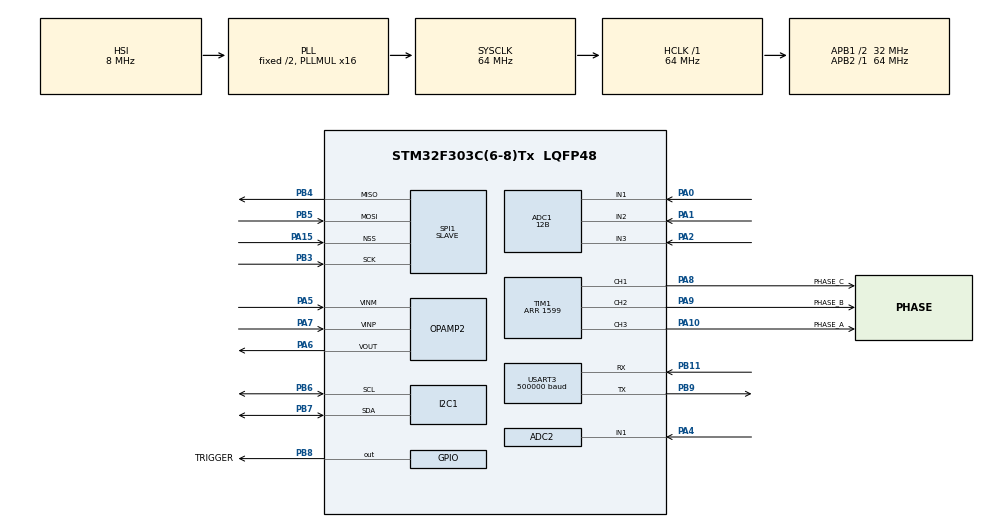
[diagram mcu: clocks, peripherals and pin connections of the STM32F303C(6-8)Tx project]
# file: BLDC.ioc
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ADC1.Channel-0\#ChannelRegularConversion=ADC_CHANNEL_1
ADC1.Channel-1\#ChannelRegularConversion=ADC_CHANNEL_2
ADC1.Channel-135\#ChannelRegularConversion=ADC_CHANNEL_1
ADC1.Channel-138\#ChannelRegularConversion=ADC_CHANNEL_2
ADC1.Channel-148\#ChannelRegularConversion=ADC_CHANNEL_3
ADC1.Channel-2\#ChannelRegularConversion=ADC_CHANNEL_3
ADC1.Channel-IN2=ADC_CHANNEL_2
ADC1.Channel-IN3=ADC_CHANNEL_3
ADC1.ClockPrescaler=ADC_CLOCK_ASYNC_DIV1
ADC1.ContinuousConvMode=DISABLE
ADC1.DMAContinuousRequests=ENABLE
ADC1.DataAlign=ADC_DATAALIGN_RIGHT
ADC1.DiscontinuousConvMode=DISABLE
ADC1.EOCSelection=ADC_EOC_SINGLE_CONV
ADC1.EnableAnalogWatchDog1=false
ADC1.EnableAnalogWatchDog2=false
ADC1.EnableAnalogWatchDog3=false
ADC1.EnableInjectedConversion=ENABLE
ADC1.EnableRegularConversion=ENABLE
ADC1.ExternalTrigConv=ADC_EXTERNALTRIGCONV_T1_TRGO2
ADC1.ExternalTrigConvEdge=ADC_EXTERNALTRIGCONVEDGE_RISING
ADC1.InjNumberOfConversion=0
ADC1.LowPowerAutoWait=DISABLE
ADC1.NbrOfConversion=3
ADC1.NbrOfConversionFlag=1
ADC1.Offset-0\#ChannelRegularConversion=0
ADC1.Offset-1\#ChannelRegularConversion=0
ADC1.Offset-135\#ChannelRegularConversion=0
ADC1.Offset-138\#ChannelRegularConversion=0
ADC1.Offset-148\#ChannelRegularConversion=0
ADC1.Offset-2\#ChannelRegularConversion=0
ADC1.OffsetNumber-0\#ChannelRegularConversion=ADC_OFFSET_NONE
ADC1.OffsetNumber-1\#ChannelRegularConversion=ADC_OFFSET_NONE
ADC1.OffsetNumber-135\#ChannelRegularConversion=ADC_OFFSET_NONE
ADC1.OffsetNumber-138\#ChannelRegularConversion=ADC_OFFSET_NONE
ADC1.OffsetNumber-148\#ChannelRegularConversion=ADC_OFFSET_NONE
ADC1.OffsetNumber-2\#ChannelRegularConversion=ADC_OFFSET_NONE
ADC1.Overrun=ADC_OVR_DATA_OVERWRITTEN
ADC1.Rank-0\#ChannelRegularConversion=1
ADC1.Rank-1\#ChannelRegularConversion=2
ADC1.Rank-135\#ChannelRegularConversion=1
ADC1.Rank-138\#ChannelRegularConversion=2
ADC1.Rank-148\#ChannelRegularConversion=3
ADC1.Rank-2\#ChannelRegularConversion=3
ADC1.Resolution=ADC_RESOLUTION_12B
ADC1.SamplingTime-0\#ChannelRegularConversion=ADC_SAMPLETIME_4CYCLES_5
ADC1.SamplingTime-1\#ChannelRegularConversion=ADC_SAMPLETIME_4CYCLES_5
ADC1.SamplingTime-135\#ChannelRegularConversion=ADC_SAMPLETIME_4CYCLES_5
ADC1.SamplingTime-138\#ChannelRegularConversion=ADC_SAMPLETIME_4CYCLES_5
ADC1.SamplingTime-148\#ChannelRegularConversion=ADC_SAMPLETIME_4CYCLES_5
ADC1.SamplingTime-2\#ChannelRegularConversion=ADC_SAMPLETIME_4CYCLES_5
ADC1.ScanConvMode=ADC_SCAN_ENABLE
ADC1.SubFamily=STM32F303x8
ADC1.master=1
ADC2.Channel-93\#ChannelRegularConversion=ADC_CHANNEL_3
ADC2.Channel-94\#ChannelRegularConversion=ADC_CHANNEL_1
ADC2.ClockPrescaler=ADC_CLOCK_ASYNC_DIV1
ADC2.ContinuousConvMode=DISABLE
ADC2.DMAContinuousRequests=ENABLE
ADC2.DataAlign=ADC_DATAALIGN_RIGHT
ADC2.DiscontinuousConvMode=DISABLE
ADC2.EOCSelection=ADC_EOC_SINGLE_CONV
ADC2.EnableAnalogWatchDog1=false
ADC2.EnableAnalogWatchDog2=false
ADC2.EnableAnalogWatchDog3=false
ADC2.EnableInjectedConversion=ENABLE
ADC2.EnableRegularConversion=ENABLE
ADC2.ExternalTrigConv=ADC_EXTERNALTRIGCONV_T15_TRGO
ADC2.ExternalTrigConvEdge=ADC_EXTERNALTRIGCONVEDGE_RISING
ADC2.InjNumberOfConversion=0
ADC2.LowPowerAutoWait=DISABLE
ADC2.NbrOfConversion=2
ADC2.NbrOfConversionFlag=1
ADC2.Offset-93\#ChannelRegularConversion=0
ADC2.Offset-94\#ChannelRegularConversion=0
ADC2.OffsetNumber-93\#ChannelRegularConversion=ADC_OFFSET_NONE
ADC2.OffsetNumber-94\#ChannelRegularConversion=ADC_OFFSET_NONE
ADC2.Overrun=ADC_OVR_DATA_OVERWRITTEN
ADC2.Rank-93\#ChannelRegularConversion=1
ADC2.Rank-94\#ChannelRegularConversion=2
ADC2.Resolution=ADC_RESOLUTION_12B
ADC2.SamplingTime-93\#ChannelRegularConversion=ADC_SAMPLETIME_7CYCLES_5
ADC2.SamplingTime-94\#ChannelRegularConversion=ADC_SAMPLETIME_7CYCLES_5
ADC2.ScanConvMode=ADC_SCAN_ENABLE
ADC2.SubFamily=STM32F303x8
Dma.ADC1.0.Direction=DMA_PERIPH_TO_MEMORY
Dma.ADC1.0.Instance=DMA1_Channel1
Dma.ADC1.0.MemDataAlignment=DMA_MDATAALIGN_HALFWORD
Dma.ADC1.0.MemInc=DMA_MINC_ENABLE
Dma.ADC1.0.Mode=DMA_CIRCULAR
Dma.ADC1.0.PeriphDataAlignment=DMA_PDATAALIGN_HALFWORD
Dma.ADC1.0.PeriphInc=DMA_PINC_DISABLE
Dma.ADC1.0.Priority=DMA_PRIORITY_LOW
Dma.ADC2.1.Direction=DMA_PERIPH_TO_MEMORY
Dma.ADC2.1.Instance=DMA1_Channel4
Dma.ADC2.1.MemDataAlignment=DMA_MDATAALIGN_HALFWORD
Dma.ADC2.1.MemInc=DMA_MINC_ENABLE
Dma.ADC2.1.Mode=DMA_CIRCULAR
Dma.ADC2.1.PeriphDataAlignment=DMA_PDATAALIGN_HALFWORD
Dma.ADC2.1.PeriphInc=DMA_PINC_DISABLE
Dma.ADC2.1.Priority=DMA_PRIORITY_LOW
Dma.Request0=ADC1
Dma.Request1=ADC2
Dma.Request2=SPI1_RX
Dma.Request3=SPI1_TX
Dma.Request4=USART3_TX
Dma.SPI1_RX.2.Direction=DMA_PERIPH_TO_MEMORY
Dma.SPI1_RX.2.Instance=DMA1_Channel6
Dma.SPI1_RX.2.MemDataAlignment=DMA_MDATAALIGN_BYTE
Dma.SPI1_RX.2.MemInc=DMA_MINC_ENABLE
Dma.SPI1_RX.2.Mode=DMA_NORMAL
Dma.SPI1_RX.2.PeriphDataAlignment=DMA_PDATAALIGN_BYTE
Dma.SPI1_RX.2.PeriphInc=DMA_PINC_DISABLE
Dma.SPI1_RX.2.Priority=DMA_PRIORITY_LOW
Dma.SPI1_TX.3.Direction=DMA_MEMORY_TO_PERIPH
Dma.SPI1_TX.3.Instance=DMA1_Channel3
Dma.SPI1_TX.3.MemDataAlignment=DMA_MDATAALIGN_BYTE
Dma.SPI1_TX.3.MemInc=DMA_MINC_ENABLE
Dma.SPI1_TX.3.Mode=DMA_NORMAL
Dma.SPI1_TX.3.PeriphDataAlignment=DMA_PDATAALIGN_BYTE
Dma.SPI1_TX.3.PeriphInc=DMA_PINC_DISABLE
Dma.SPI1_TX.3.Priority=DMA_PRIORITY_LOW
Dma.USART3_TX.4.Direction=DMA_MEMORY_TO_PERIPH
Dma.USART3_TX.4.Instance=DMA1_Channel2
Dma.USART3_TX.4.MemDataAlignment=DMA_MDATAALIGN_BYTE
Dma.USART3_TX.4.MemInc=DMA_MINC_ENABLE
Dma.USART3_TX.4.Mode=DMA_NORMAL
Dma.USART3_TX.4.PeriphDataAlignment=DMA_PDATAALIGN_BYTE
Dma.USART3_TX.4.PeriphInc=DMA_PINC_DISABLE
Dma.USART3_TX.4.Priority=DMA_PRIORITY_LOW
FREERTOS.INCLUDE_vTaskDelayUntil=1
FREERTOS.Tasks01=defaultTask,0,512,StartDefaultTask,Default,NULL,Dynamic,NULL,NULL
FREERTOS.configTOTAL_HEAP_SIZE=7000
Mcu.Family=STM32F3
Mcu.Name=STM32F303C(6-8)Tx
Mcu.Package=LQFP48
NVIC.ADC1_2_IRQn=true\:5\:0\:false\:false\:true\:true\:true\:true
NVIC.DMA1_Channel1_IRQn=true\:0\:0\:false\:false\:true\:false\:false\:true
NVIC.DMA1_Channel2_IRQn=true\:0\:0\:true\:false\:true\:false\:false\:true
NVIC.DMA1_Channel3_IRQn=true\:5\:0\:false\:false\:true\:true\:false\:true
NVIC.DMA1_Channel4_IRQn=true\:5\:0\:false\:false\:true\:true\:false\:true
NVIC.DMA1_Channel6_IRQn=true\:5\:0\:false\:false\:true\:true\:false\:true
NVIC.I2C1_EV_IRQn=true\:5\:0\:false\:false\:true\:true\:true\:true
NVIC.PriorityGroup=NVIC_PRIORITYGROUP_4
NVIC.TIM1_TRG_COM_TIM17_IRQn=true\:0\:0\:false\:false\:true\:false\:false\:true
NVIC.TIM6_DAC1_IRQn=true\:0\:0\:false\:false\:true\:false\:false\:true
NVIC.TimeBase=TIM6_DAC1_IRQn
NVIC.TimeBaseIP=TIM6
PA0.Mode=IN1-Single-Ended
PA0.Signal=ADC1_IN1
PA1.Mode=IN2-Single-Ended
PA1.Signal=ADC1_IN2
PA10.GPIO_Label=PHASE_A
PA10.GPIO_Speed=GPIO_SPEED_FREQ_HIGH
PA10.Signal=S_TIM1_CH3
PA13.Mode=Serial_Wire
PA13.Signal=SYS_JTMS-SWDIO
PA14.Mode=Serial_Wire
PA14.Signal=SYS_JTCK-SWCLK
PA15.Mode=NSS_Signal_Hard_Input
PA15.Signal=SPI1_NSS
PA2.Mode=IN3-Single-Ended
PA2.Signal=ADC1_IN3
PA4.Mode=IN1-Single-Ended
PA4.Signal=ADC2_IN1
PA5.Mode=Standalone
PA5.Signal=OPAMP2_VINM
PA6.Mode=Standalone
PA6.Signal=OPAMP2_VOUT
PA7.Mode=Standalone
PA7.Signal=OPAMP2_VINP
PA8.GPIO_Label=PHASE_C
PA8.GPIO_Speed=GPIO_SPEED_FREQ_HIGH
PA8.Signal=S_TIM1_CH1
PA9.GPIO_Label=PHASE_B
PA9.GPIO_Speed=GPIO_SPEED_FREQ_HIGH
PA9.Signal=S_TIM1_CH2
PB11.Mode=Asynchronous
PB11.Signal=USART3_RX
PB3.Mode=Full_Duplex_Slave
PB3.Signal=SPI1_SCK
PB4.Mode=Full_Duplex_Slave
PB4.Signal=SPI1_MISO
PB5.Mode=Full_Duplex_Slave
PB5.Signal=SPI1_MOSI
PB6.Mode=I2C
PB6.Signal=I2C1_SCL
PB7.Mode=I2C
PB7.Signal=I2C1_SDA
PB8.GPIO_Label=TRIGGER
PB8.Signal=GPIO_Output
PB9.Mode=Asynchronous
PB9.Signal=USART3_TX
ProjectManager.HeapSize=0x200
ProjectManager.StackSize=0x400
ProjectManager.TargetToolchain=Makefile
RCC.AHBFreq_Value=64000000
RCC.APB1CLKDivider=RCC_HCLK_DIV2
RCC.APB1Freq_Value=32000000
RCC.APB1TimFreq_Value=64000000
RCC.APB2Freq_Value=64000000
RCC.APB2TimFreq_Value=64000000
RCC.CortexFreq_Value=64000000
RCC.FLatency=FLASH_LATENCY_2
RCC.HCLKFreq_Value=64000000
RCC.HSE_VALUE=8000000
RCC.HSI_VALUE=8000000
RCC.LSE_VALUE=32768
RCC.PLLMUL=RCC_PLL_MUL16
RCC.SYSCLKFreq_VALUE=64000000
RCC.SYSCLKSourceVirtual=RCC_SYSCLKSOURCE_PLLCLK
SH.S_TIM1_CH1.0=TIM1_CH1,PWM Generation1 CH1
SH.S_TIM1_CH2.0=TIM1_CH2,PWM Generation2 CH2
SH.S_TIM1_CH3.0=TIM1_CH3,PWM Generation3 CH3
SPI1.DataSize=SPI_DATASIZE_8BIT
SPI1.Direction=SPI_DIRECTION_2LINES
SPI1.Mode=SPI_MODE_SLAVE
SPI1.VirtualNSS=VM_NSSHARD
SPI1.VirtualType=VM_SLAVE
TIM1.Channel-Output\ Compare4\ No\ Output=TIM_CHANNEL_4
TIM1.Channel-PWM\ Generation1\ CH1=TIM_CHANNEL_1
TIM1.Channel-PWM\ Generation2\ CH2=TIM_CHANNEL_2
TIM1.Channel-PWM\ Generation3\ CH3=TIM_CHANNEL_3
TIM1.OCMode_4=TIM_OCMODE_TOGGLE
TIM1.Period=1599
TIM1.Pulse-Output\ Compare4\ No\ Output=112
TIM1.TIM_MasterOutputTrigger=TIM_TRGO_RESET
TIM1.TIM_MasterOutputTrigger2=TIM_TRGO2_OC4REF_RISINGFALLING
TIM1.TIM_MasterSlaveMode=TIM_MASTERSLAVEMODE_ENABLE
TIM15.Period=31
TIM15.TIM_MasterOutputTrigger=TIM_TRGO_UPDATE
TIM15.TIM_MasterSlaveMode=TIM_MASTERSLAVEMODE_ENABLE
TIM2.Period=1
TIM2.TIM_MasterOutputTrigger=TIM_TRGO_UPDATE
TIM2.TIM_MasterSlaveMode=TIM_MASTERSLAVEMODE_ENABLE
USART3.BaudRate=500000
USART3.VirtualMode-Asynchronous=VM_ASYNC
VP_ADC2_OPAMP_OUT2.Mode=IN3-OPAMP2-Single-Ended
VP_FREERTOS_VS_CMSIS_V1.Mode=CMSIS_V1
VP_SYS_VS_tim6.Mode=TIM6
VP_TIM15_VS_ClockSourceITR.Mode=TriggerSource_ITR0
VP_TIM15_VS_ControllerModeClock.Mode=Clock Mode
VP_TIM1_VS_ClockSourceITR.Mode=TriggerSource_ITR1
VP_TIM1_VS_ControllerModeClock.Mode=Clock Mode
VP_TIM1_VS_no_output4.Mode=Output Compare4 No Output
VP_TIM2_VS_ClockSourceINT.Mode=Internal
board=BLDC

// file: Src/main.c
/* USER CODE BEGIN Header */
/**
  ******************************************************************************
  * @file           : main.c
  * @brief          : Main program body
  ******************************************************************************
  * @attention
  *
  * <h2><center>&copy; Copyright (c) 2020 STMicroelectronics.
  * All rights reserved.</center></h2>
  *
  * This software component is licensed by ST under Ultimate Liberty license
  * SLA0044, the "License"; You may not use this file except in compliance with
  * the License. You may obtain a copy of the License at:
  *                             www.st.com/SLA0044
  *
  ******************************************************************************
  */
/* USER CODE END Header */

#include "main.h"
#include "cmsis_os.h"
#include "adc.h"
#include "dma.h"
#include "i2c.h"
#include "opamp.h"
#include "spi.h"
#include "tim.h"
#include "usart.h"
#include "gpio.h"

/* USER CODE BEGIN PV */
/* Private variables ---------------------------------------------------------*/

/* USER CODE END PV */

void SystemClock_Config(void);
void MX_FREERTOS_Init(void);
/* USER CODE BEGIN PFP */
/* Private function prototypes -----------------------------------------------*/

/* USER CODE END PFP */

int main(void)
{

  /* MCU Configuration--------------------------------------------------------*/

  /* Reset of all peripherals, Initializes the Flash interface and the Systick. */
  HAL_Init();

  /* Configure the system clock */
  SystemClock_Config();

  /* Initialize all configured peripherals */
  MX_GPIO_Init();
  MX_DMA_Init();
  MX_OPAMP2_Init();
  MX_SPI1_Init();
  MX_TIM1_Init();
  MX_ADC1_Init();
  MX_I2C1_Init();
  MX_TIM2_Init();
  MX_ADC2_Init();
  MX_TIM15_Init();
  MX_USART3_UART_Init();

  /* Call init function for freertos objects (in freertos.c) */
  MX_FREERTOS_Init();

  /* Start scheduler */
  osKernelStart();

  /* We should never get here as control is now taken by the scheduler */

  /* Infinite loop */
  while (1)
  {

  }
}

void SystemClock_Config(void)
{
  RCC_OscInitTypeDef RCC_OscInitStruct = {0};
  RCC_ClkInitTypeDef RCC_ClkInitStruct = {0};
  RCC_PeriphCLKInitTypeDef PeriphClkInit = {0};

  /** Initializes the CPU, AHB and APB busses clocks
  */
  RCC_OscInitStruct.OscillatorType = RCC_OSCILLATORTYPE_HSI;
  RCC_OscInitStruct.HSIState = RCC_HSI_ON;
  RCC_OscInitStruct.HSICalibrationValue = RCC_HSICALIBRATION_DEFAULT;
  RCC_OscInitStruct.PLL.PLLState = RCC_PLL_ON;
  RCC_OscInitStruct.PLL.PLLSource = RCC_PLLSOURCE_HSI;
  RCC_OscInitStruct.PLL.PLLMUL = RCC_PLL_MUL16;
  if (HAL_RCC_OscConfig(&RCC_OscInitStruct) != HAL_OK)
  {
    Error_Handler();
  }
  /** Initializes the CPU, AHB and APB busses clocks
  */
  RCC_ClkInitStruct.ClockType = RCC_CLOCKTYPE_HCLK|RCC_CLOCKTYPE_SYSCLK
                              |RCC_CLOCKTYPE_PCLK1|RCC_CLOCKTYPE_PCLK2;
  RCC_ClkInitStruct.SYSCLKSource = RCC_SYSCLKSOURCE_PLLCLK;
  RCC_ClkInitStruct.AHBCLKDivider = RCC_SYSCLK_DIV1;
  RCC_ClkInitStruct.APB1CLKDivider = RCC_HCLK_DIV2;
  RCC_ClkInitStruct.APB2CLKDivider = RCC_HCLK_DIV1;

  if (HAL_RCC_ClockConfig(&RCC_ClkInitStruct, FLASH_LATENCY_2) != HAL_OK)
  {
    Error_Handler();
  }
  PeriphClkInit.PeriphClockSelection = RCC_PERIPHCLK_I2C1|RCC_PERIPHCLK_TIM1
                              |RCC_PERIPHCLK_ADC12;
  PeriphClkInit.Adc12ClockSelection = RCC_ADC12PLLCLK_DIV1;
  PeriphClkInit.I2c1ClockSelection = RCC_I2C1CLKSOURCE_HSI;
  PeriphClkInit.Tim1ClockSelection = RCC_TIM1CLK_HCLK;
  if (HAL_RCCEx_PeriphCLKConfig(&PeriphClkInit) != HAL_OK)
  {
    Error_Handler();
  }
}

void HAL_TIM_PeriodElapsedCallback(TIM_HandleTypeDef *htim)
{
  if (htim->Instance == TIM6) {
    HAL_IncTick();
  }
}

void Error_Handler(void)
{
  while(1)
  {
  }
}

/************************ (C) COPYRIGHT STMicroelectronics *****END OF FILE****/

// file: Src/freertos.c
/* USER CODE BEGIN Header */
/**
  ******************************************************************************
  * File Name          : freertos.c
  * Description        : Code for freertos applications
  ******************************************************************************
  * @attention
  *
  * <h2><center>&copy; Copyright (c) 2020 STMicroelectronics.
  * All rights reserved.</center></h2>
  *
  * This software component is licensed by ST under Ultimate Liberty license
  * SLA0044, the "License"; You may not use this file except in compliance with
  * the License. You may obtain a copy of the License at:
  *                             www.st.com/SLA0044
  *
  ******************************************************************************
  */
/* USER CODE END Header */

#include "FreeRTOS.h"
#include "task.h"
#include "main.h"
#include "cmsis_os.h"

osThreadId defaultTaskHandle;

void StartDefaultTask(void const * argument);

void MX_FREERTOS_Init(void); /* (MISRA C 2004 rule 8.1) */

void MX_FREERTOS_Init(void) {

  /* Create the thread(s) */
  /* definition and creation of defaultTask */
  osThreadDef(defaultTask, StartDefaultTask, osPriorityNormal, 0, 512);
  defaultTaskHandle = osThreadCreate(osThread(defaultTask), NULL);

}

void StartDefaultTask(void const * argument)
{

  /* USER CODE BEGIN StartDefaultTask */
#include "../HAL/Startup.h"
	Start();
  /* Infinite loop */
  for(;;)
  {
    osDelay(1);
  }
  /* USER CODE END StartDefaultTask */
}

/************************ (C) COPYRIGHT STMicroelectronics *****END OF FILE****/
